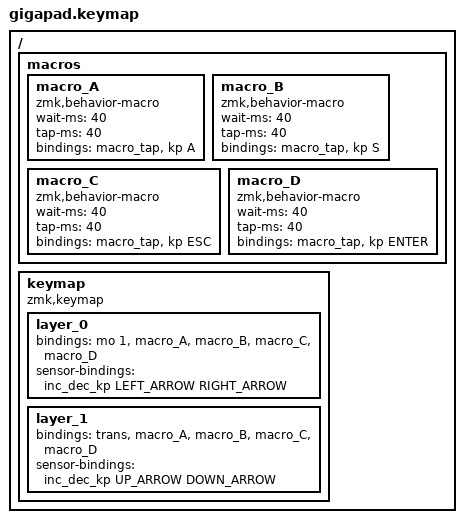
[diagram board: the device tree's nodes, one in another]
#include <behaviors.dtsi>
#include <dt-bindings/zmk/keys.h>


/ {
    macros {
        macro_A: macro_A {
            compatible = "zmk,behavior-macro";
            #binding-cells = <0>;
            wait-ms = <40>;
            tap-ms = <40>;
            bindings = 
                <&macro_tap &kp A>;
        };
        macro_B: macro_B {
            compatible = "zmk,behavior-macro";
            #binding-cells = <0>;
            wait-ms = <40>;
            tap-ms = <40>;
            bindings = 
                <&macro_tap &kp S>;
        };
        macro_C: macro_C {
            compatible = "zmk,behavior-macro";
            #binding-cells = <0>;
            wait-ms = <40>;
            tap-ms = <40>;
            bindings = 
                <&macro_tap &kp ESC>;
        };
        macro_D: macro_D {
            compatible = "zmk,behavior-macro";
            #binding-cells = <0>;
            wait-ms = <40>;
            tap-ms = <40>;
            bindings = 
                <&macro_tap &kp ENTER>;
        };
    };

    keymap {
        compatible = "zmk,keymap";

        layer_0 {
            bindings = <
&mo 1   &macro_A   &macro_B   &macro_C  &macro_D
            >;

            sensor-bindings = <&inc_dec_kp LEFT_ARROW RIGHT_ARROW>;
        };

        layer_1 {
            bindings = <
&trans  &macro_A   &macro_B   &macro_C  &macro_D
            >;

            sensor-bindings = <&inc_dec_kp UP_ARROW DOWN_ARROW>;
        };
    };
};
